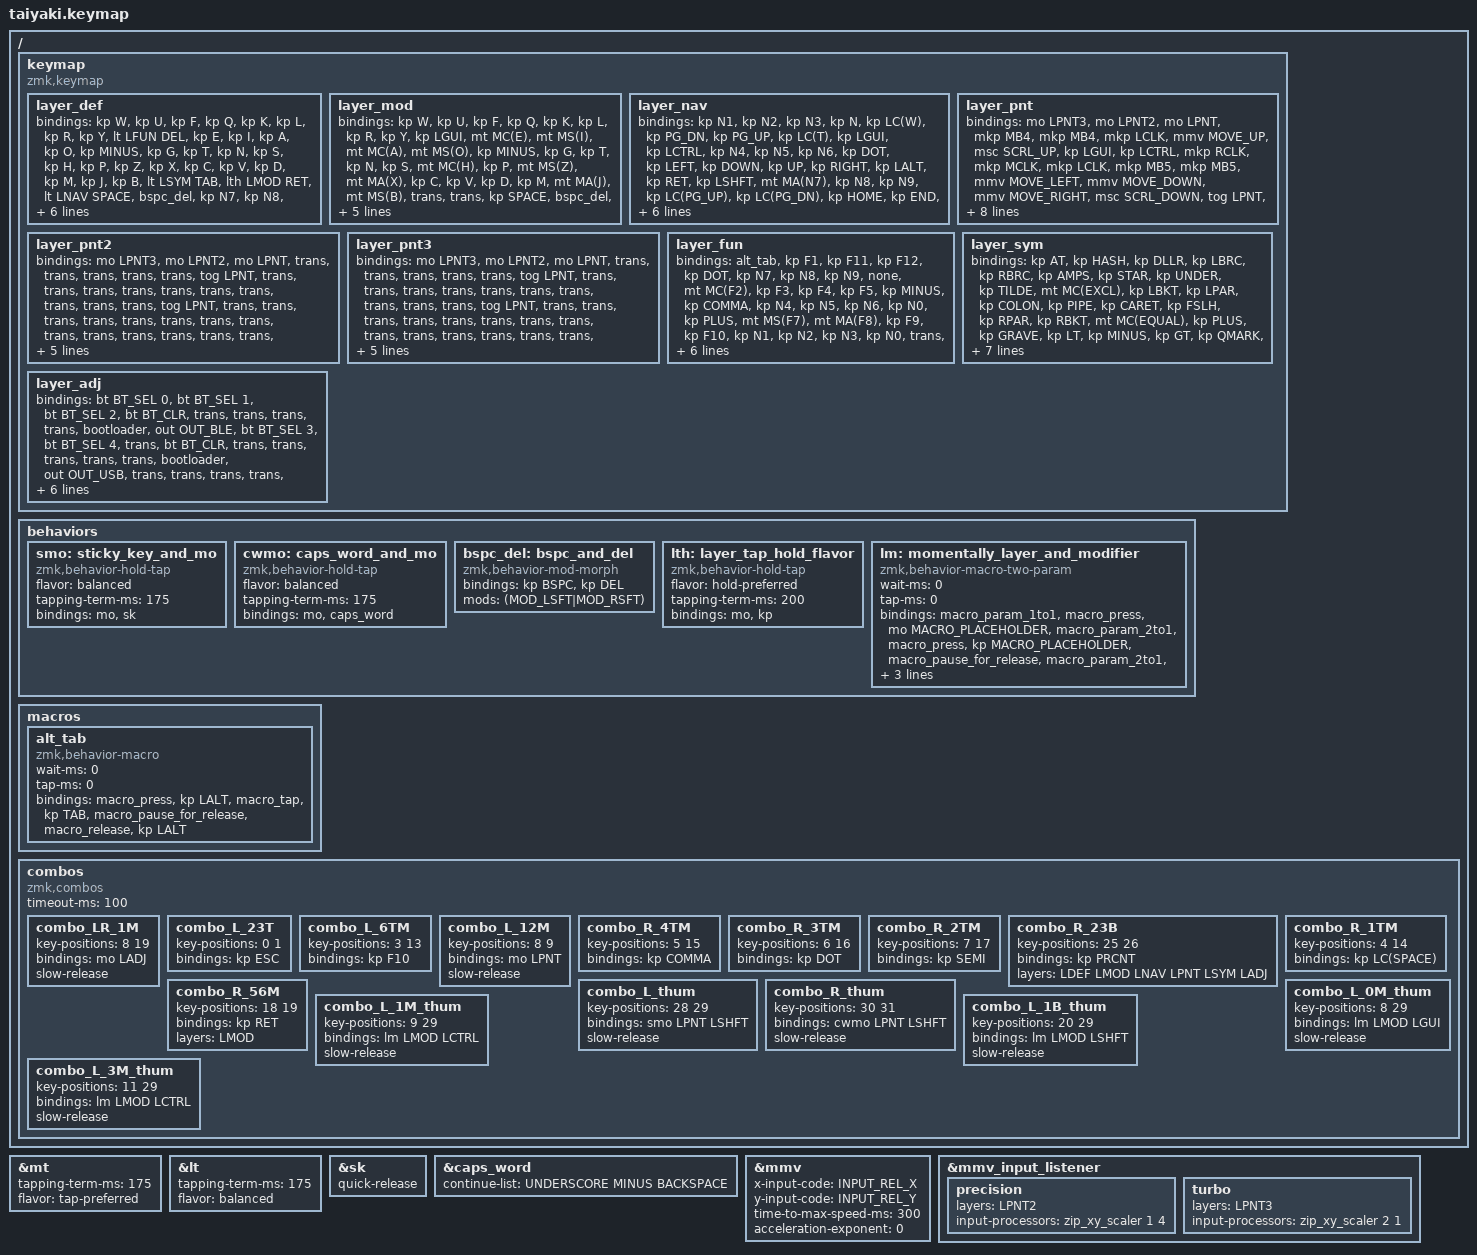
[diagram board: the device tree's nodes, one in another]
#include <behaviors.dtsi>
#include <dt-bindings/zmk/keys.h>
#include <dt-bindings/zmk/bt.h>
#include <dt-bindings/zmk/outputs.h>
#include <dt-bindings/zmk/pointing.h>
#include <input/processors.dtsi>

/*
        ////////////////////
        // layer settings //
        ////////////////////
*/
#define LDEF 0
#define LMOD 1
#define LNAV 2
#define LPNT 3
#define LPNT2 4
#define LPNT3 5
#define LFUN 6
#define LSYM 7
#define LADJ 8
/{
    keymap {
        compatible = "zmk,keymap";
        layer_def:layer_def{};
        layer_mod:layer_mod{};
        layer_nav:layer_nav{};
        layer_pnt:layer_pnt{};
        layer_pnt2:layer_pnt2{};
        layer_pnt3:layer_pnt3{};
        layer_fun:layer_fun{};
        layer_sym:layer_sym{};
        layer_adj:layer_adj{};
    };
};

/*
        //////////////////////////
        // custom key behaviors //
        //////////////////////////
*/
// macro for mod tap
#define MC(X) LCTRL X
#define MS(X) LSHFT X
#define MA(X) LALT X
#define MG(X) LGUI X

&mt {
    tapping-term-ms = <175>;
    flavor = "tap-preferred";
};
&lt {
    tapping-term-ms = <175>;
    flavor = "balanced";
};
&sk {
    quick-release;
};
&caps_word {
    continue-list = <UNDERSCORE MINUS BACKSPACE>;
};
&mmv {
    x-input-code = <INPUT_REL_X>;
    y-input-code = <INPUT_REL_Y>;
    time-to-max-speed-ms = <300>;
    acceleration-exponent = <0>;
};
&mmv_input_listener {
    precision {
        layers = <LPNT2>;
        input-processors = <&zip_xy_scaler 1 4>;
    };
    turbo {
        layers = <LPNT3>;
        input-processors = <&zip_xy_scaler 2 1>;
    };
};


/ {
    behaviors {
        // original behaviors
        smo: sticky_key_and_mo {
            // &smo LFUN LSHFT : tap to sticky shift, hold to function layer
            compatible = "zmk,behavior-hold-tap";
            #binding-cells = <2>;
            flavor = "balanced";
            tapping-term-ms = <175>;
            bindings = <&mo>, <&sk>;
        };
        cwmo: caps_word_and_mo {
            // &cwmo LFUN DUMMY : tap to caps_word, hold to function layer
            compatible = "zmk,behavior-hold-tap";
            #binding-cells = <2>;
            flavor = "balanced";
            tapping-term-ms = <175>;
            bindings = <&mo>, <&caps_word>;
        };
        bspc_del: bspc_and_del{
            compatible = "zmk,behavior-mod-morph";
            #binding-cells = <0>;
            bindings = <&kp BSPC>, <&kp DEL>;
            mods = <(MOD_LSFT|MOD_RSFT)>;
        };

        // behaviors for mod layer
        lth: layer_tap_hold_flavor {
            compatible = "zmk,behavior-hold-tap";
            #binding-cells = <2>;
            flavor = "hold-preferred";
            tapping-term-ms = <200>;
            bindings = <&mo>, <&kp>;
        };
        lm: momentally_layer_and_modifier {
            // activate momentally layer and press (modifier) key
            // &lm LMOD LCTRL : activate modifier layer with LCTRL hold
            compatible = "zmk,behavior-macro-two-param";
            wait-ms = <0>;
            tap-ms = <0>;
            #binding-cells = <2>;
            bindings
                = <&macro_param_1to1>
                , <&macro_press &mo MACRO_PLACEHOLDER>
                , <&macro_param_2to1>
                , <&macro_press &kp MACRO_PLACEHOLDER>
                , <&macro_pause_for_release>
                , <&macro_param_2to1>
                , <&macro_release &kp MACRO_PLACEHOLDER>
                , <&macro_param_1to1>
                , <&macro_release &mo MACRO_PLACEHOLDER>
                ;
        };
    };

    macros {
        // alt+tab on tap, continue to press alt on hold. 
        alt_tab: alt_tab {
            compatible = "zmk,behavior-macro";
            #binding-cells = <0>;
            wait-ms = <0>;
            tap-ms = <0>;
            bindings
                = <&macro_press &kp LALT>
                , <&macro_tap &kp TAB>
                , <&macro_pause_for_release>
                , <&macro_release &kp LALT>
                ;
        };
    };
};


/*
        ////////////
        // combos //
        ////////////
*/
/{
      // 32 - 12 - 14
      //  44    45 00 01 02 03    04 05 06 07 46 47     32 33 34
      //  48 08 09 10 11 12 13    14 15 16 17 18 19 49  35 36 37
      //  50    20 21 22 23    51    24 25 26 27 52     38 39 40
      //  53 54 55       28 29    30 31    56 57 58 59  41 42 43
    combos {
        compatible = "zmk,combos";
        timeout-ms = <100>;

        //adj
        combo_LR_1M {
            key-positions = <8 19>;
            bindings = <&mo LADJ>;
            slow-release;
        };

        //left basic
        combo_L_23T {
            key-positions = <0 1>;
            bindings = <&kp ESC>;
        };
        combo_L_6TM {
            key-positions = <3 13>;
            bindings = <&kp F10>;
        };
        combo_L_12M {
            key-positions = <8 9>;
            bindings = <&mo LPNT>;
            slow-release;
        };

        // right basic
        combo_R_4TM {
            key-positions = <5 15>;
            bindings = <&kp COMMA>;
        };
        combo_R_3TM {
            key-positions = <6 16>;
            bindings = <&kp DOT>;
        };
        combo_R_2TM {
            key-positions = <7 17>;
            bindings = <&kp SEMI>;
        };
        combo_R_23B {
            key-positions = <25 26>;
            bindings = <&kp PRCNT>;
            layers = < LDEF LMOD LNAV LPNT LSYM LADJ >;
        };
        combo_R_1TM {
            key-positions = <4 14>;
            bindings = <&kp LC(SPACE)>;
        };
        combo_R_56M {
            key-positions = <18 19>;
            bindings = <&kp RET>;
            layers = <LMOD>;
        };

        // thum
        combo_L_thum {
            key-positions = <28 29>;
            bindings = <&smo LPNT LSHFT>;
            slow-release;
        };
        combo_R_thum {
            key-positions = <30 31>;
            bindings = <&cwmo LPNT LSHFT>;
            slow-release;
        };

        // thum mod
        combo_L_1M_thum { // ctrl
            key-positions = <9 29>;
            bindings = <&lm LMOD LCTRL>;
            slow-release;
        };
        combo_L_1B_thum { // shift
            key-positions = <20 29>;
            bindings = <&lm LMOD LSHFT>;
            slow-release;
        };
        combo_L_0M_thum { // gui
            key-positions = <8 29>;
            bindings = <&lm LMOD LGUI>;
            slow-release;
        };
        combo_L_3M_thum { // ctrl
            key-positions = <11 29>;
            bindings = <&lm LMOD LCTRL>;
            slow-release;
        };
    };
};


/*
        /////////////
        // keymaps //
        /////////////
*/


&layer_def {
    bindings = < 
                     &kp W  &kp U &kp F &kp  Q          &kp K &kp L &kp R &kp Y   
&lt LFUN DEL  &kp E &kp I  &kp A &kp O &kp MINUS       &kp G &kp T &kp N &kp S &kp H &kp P
               &kp Z &kp X  &kp C &kp V                       &kp D &kp M &kp J &kp B 
                   &lt LSYM TAB &lth LMOD RET           &lt LNAV SPACE &bspc_del
                   
&kp N7 &kp N8 &kp N9
&kp N4 &kp N5 &kp N6
&kp N1 &kp N2 &kp N3
&kp N0 &kp N0 &kp DOT 
&kp ESC &mo LPNT                      &kp DEL &kp BSPC
&lt LFUN ESC                                   &kp RET 
&kp LSHFT               &mo LADJ      &kp UP
&kp LCTRL &kp LGUI &kp LALT &kp LALT &kp LEFT &kp DOWN &kp RIGHT
        >;
};

&layer_mod {
    bindings = <
                    &kp W      &kp U     &kp F     &kp Q        &kp K &kp L &kp R &kp Y   
&kp LGUI  &mt MC(E) &mt MS(I)  &mt MC(A) &mt MS(O) &kp MINUS    &kp G &kp T &kp N &kp S     &mt MC(H) &kp P
          &mt MS(Z) &mt MA(X)  &kp C     &kp V                        &kp D &kp M &mt MA(J) &mt MS(B) 
                                 &trans   &trans                 &kp SPACE &bspc_del

&trans &trans &trans
&trans &trans &trans
&trans &trans &trans
&trans &trans &trans
&trans &trans   &trans &trans
&trans                 &trans
&trans      &trans     &trans
&trans &trans &trans  &trans &trans &trans &trans
    >;
};

&layer_nav {
    bindings = <
                    &kp N1        &kp N2      &kp N3    &kp N       &kp LC(W) &kp PG_DN     &kp PG_UP     &kp LC(T)
&kp LGUI &kp LCTRL  &kp N4        &kp N5      &kp N6    &kp DOT     &kp LEFT  &kp DOWN      &kp UP        &kp RIGHT &kp LALT &kp RET
         &kp LSHFT  &mt MA(N7)    &kp N8      &kp N9                          &kp LC(PG_UP) &kp LC(PG_DN) &kp HOME  &kp END    
                                  &trans    &kp RET                           &kp SPACE   &bspc_del

&trans &trans &trans
&trans &trans &trans
&trans &trans &trans
&trans &trans &trans
&trans &trans   &trans &trans
&trans                 &trans
&trans      &trans     &trans
&trans &trans &trans  &trans &trans &trans &trans
    >;
};

&layer_pnt{
    bindings = <
                       &mo LPNT3 &mo LPNT2 &mo LPNT   &mkp MB4       &mkp MB4  &mkp LCLK      &mmv MOVE_UP   &msc SCRL_UP
  &kp LGUI  &kp LCTRL  &mkp RCLK &mkp MCLK &mkp LCLK  &mkp MB5       &mkp MB5  &mmv MOVE_LEFT &mmv MOVE_DOWN &mmv MOVE_RIGHT &msc SCRL_DOWN  &tog LPNT
            &kp LSHFT  &kp LALT  &kp LC(C) &kp LC(V)                           &kp LC(T)      &kp LC(W)      &msc SCRL_LEFT  &msc SCRL_RIGHT      
                      &trans   &trans                  &kp SPACE      &bspc_del

&trans &trans &trans
&trans &trans &trans
&trans &trans &trans
&trans &trans &trans
&trans &trans   &trans &trans
&trans                 &trans
&trans      &trans     &trans
&trans &trans &trans  &trans &trans &trans &trans
    >;
};

&layer_pnt2{
    bindings = <
                    &mo LPNT3 &mo LPNT2 &mo LPNT &trans       &trans  &trans &trans &trans
  &tog LPNT &trans  &trans    &trans    &trans   &trans       &trans  &trans &trans &trans &trans  &tog LPNT
            &trans  &trans    &trans    &trans                        &trans &trans &trans &trans      
                      &trans   &trans                  &trans      &trans

&trans &trans &trans
&trans &trans &trans
&trans &trans &trans
&trans &trans &trans
&trans &trans   &trans &trans
&trans                 &trans
&trans      &trans     &trans
&trans &trans &trans  &trans &trans &trans &trans
    >;
};

&layer_pnt3{
    bindings = <
                    &mo LPNT3 &mo LPNT2 &mo LPNT &trans       &trans  &trans &trans &trans
  &tog LPNT &trans  &trans    &trans    &trans   &trans       &trans  &trans &trans &trans &trans  &tog LPNT
            &trans  &trans    &trans    &trans                        &trans &trans &trans &trans      
                      &trans   &trans                  &trans      &trans

&trans &trans &trans
&trans &trans &trans
&trans &trans &trans
&trans &trans &trans
&trans &trans   &trans &trans
&trans                 &trans
&trans      &trans     &trans
&trans &trans &trans  &trans &trans &trans &trans
    >;
};

&layer_fun {
    bindings = <
                   &alt_tab    &kp F1  &kp F11 &kp F12     &kp DOT   &kp N7 &kp N8 &kp N9      
&none   &mt MC(F2) &kp F3      &kp F4  &kp F5  &kp MINUS   &kp COMMA &kp N4 &kp N5 &kp N6 &kp N0 &kp PLUS
        &mt MS(F7) &mt MA(F8)  &kp F9  &kp F10                       &kp N1 &kp N2 &kp N3 &kp N0      
                      &trans   &trans                  &kp SPACE &bspc_del

&trans &trans &trans
&trans &trans &trans
&trans &trans &trans
&trans &trans &trans
&trans &trans   &trans &trans
&trans                 &trans
&trans      &trans     &trans
&trans &trans &trans  &trans &trans &trans &trans
    >;
};

&layer_sym {
    bindings = <
                       &kp AT   &kp HASH   &kp DLLR  &kp LBRC    &kp RBRC   &kp AMPS   &kp STAR  &kp UNDER   
&kp TILDE &mt MC(EXCL) &kp LBKT &kp LPAR   &kp COLON &kp PIPE    &kp CARET  &kp FSLH   &kp RPAR  &kp RBKT  &mt MC(EQUAL) &kp PLUS 
          &kp GRAVE    &kp LT   &kp MINUS  &kp GT                           &kp QMARK  &kp DQT   &kp SQT   &kp BSLH 
                                &trans     &kp RET               &kp SPACE   &bspc_del

&trans &trans &trans
&trans &trans &trans
&trans &trans &trans
&trans &trans &trans
&trans &trans   &trans &trans
&trans                 &trans
&trans      &trans     &trans
&trans &trans &trans  &trans &trans &trans &trans
    >;
};

&layer_adj {
    bindings = <
                         &bt BT_SEL 0 &bt BT_SEL 1 &bt BT_SEL 2 &bt BT_CLR       &trans      &trans      &trans      &trans      
&bootloader &out OUT_BLE &bt BT_SEL 3 &bt BT_SEL 4 &trans       &bt BT_CLR       &trans      &trans      &trans      &trans      &trans      &bootloader
            &out OUT_USB &trans       &trans       &trans                                    &trans      &trans      &trans      &trans      
                                      &trans       &trans                                    &trans      &trans      

&trans &trans &trans
&trans &trans &trans
&trans &trans &trans
&trans &trans &trans
&trans &trans   &trans &trans
&trans                 &trans
&trans      &trans     &trans
&trans &trans &trans  &trans &trans &trans &trans
    >;
};
